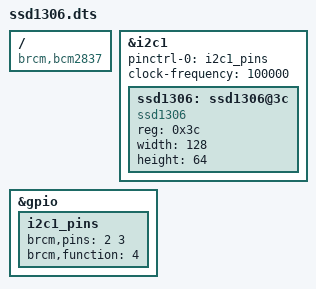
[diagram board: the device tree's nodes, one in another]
/dts-v1/;
/plugin/;

/ {
    compatible = "brcm,bcm2837";

    fragment@0 {
        target = <&i2c1>;
        __overlay__ {
            pinctrl-names = "default";
            pinctrl-0 = <&i2c1_pins>;
            clock-frequency = <100000>;
            status = "okay";

            ssd1306: ssd1306@3c {
                compatible = "ssd1306";
                reg = <0x3c>;
                width = <128>;
                height = <64>;
                status = "okay";
            };
        };
    };

    fragment@1 {
        target = <&gpio>;
        __overlay__ {
            i2c1_pins: i2c1_pins {
                brcm,pins = <2 3>;
                brcm,function = <4>; /* ALT0 (I2C) */
            };
        };
    };
}; 

